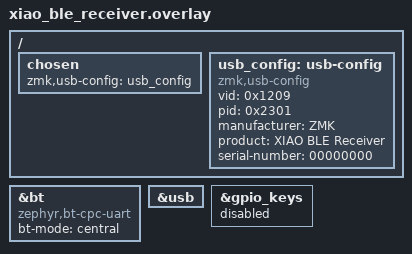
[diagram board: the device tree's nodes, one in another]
/ {
    chosen {
        zmk,usb-config = <&usb_config>;
    };

    usb_config: usb-config {
        compatible = "zmk,usb-config";
        vid = <0x1209>;
        pid = <0x2301>;
        manufacturer = "ZMK";
        product = "XIAO BLE Receiver";
        serial-number = "00000000";
    };
};

&bt {
    status = "okay";
    compatible = "zephyr,bt-cpc-uart";
    bt-mode = "central";
};

&usb {
    status = "okay";
};

&gpio_keys {
    status = "disabled";
};
